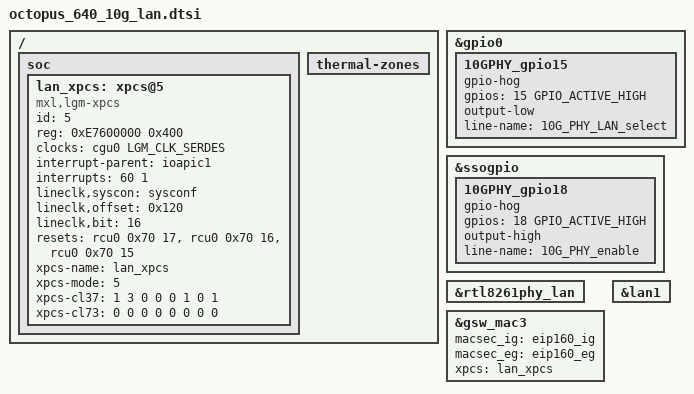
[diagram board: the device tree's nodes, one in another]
// SPDX-License-Identifier: GPL-2.0
/*
 * Copyright (C) 2024 MaxLinear, Inc.
 */

/{
	soc {
		/delete-node/ p34x@0;

		lan_xpcs: xpcs@5 {
			id = <5>;
			compatible = "mxl,lgm-xpcs";
			status = "okay";
			reg =<0xE7600000 0x400>;
			clocks = <&cgu0 LGM_CLK_SERDES>;
			interrupt-parent = <&ioapic1>;
			interrupts = <60 1>;
			lineclk,syscon = <&sysconf>;	/* chiptop */
			lineclk,offset = <0x120>;
			lineclk,bit = <16>;
			/*phys = <&lan_xpcs_phy>;*/
			resets = <
				&rcu0 0x70 17
				&rcu0 0x70 16
				&rcu0 0x70 15
			>;
			xpcs-name = "lan_xpcs";
			xpcs-mode = <5>; /* <0> - SGMII, <1> - 1000BaseX, <2> - 2500BaseX, <3> - 5GBaseR, <4> - 10GBaseR, <5> - USXGMII, <6> - 10GKR, <7> - QUSXGMII */
			xpcs-cl37 = <1 3 0 0 0 1 0 1>; /* <0> - disable, <1> - SGMII MAC side, <2> - SGMII PHY side, <3> - BaseX */
			xpcs-cl73 = <0 0 0 0 0 0 0 0>; /* <0> - disable, <1> - enable */
		};
	};

	thermal-zones {
		/delete-node/ p34-thermal;
	};
};

/* Select 10GPHY */
&gpio0 {
	10GPHY_gpio15 {
		gpio-hog;
		gpios = <15 GPIO_ACTIVE_HIGH>;
		output-low;
		line-name = "10G_PHY_LAN_select";
	};
};

&ssogpio {
	10GPHY_gpio18 { /* put 10G PHY out of reset */
		gpio-hog;
		gpios = <18 GPIO_ACTIVE_HIGH>;
		output-high;
		line-name = "10G_PHY_enable";
	};
};

&rtl8261phy_lan {
	status = "okay";
};

&gsw_mac3 {
	macsec_ig = <&eip160_ig>;
	macsec_eg = <&eip160_eg>;
	xpcs = <&lan_xpcs>;
};

&lan1 {
	status = "okay";
};
